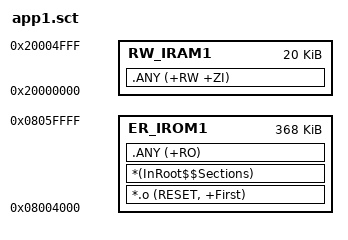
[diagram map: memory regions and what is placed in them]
; *************************************************************
; *** APP1 Scatter-Loading Description File ***
; *************************************************************

LR_IROM1 0x08004000 0x00005C00  {    ; APP1区域: 24KB
  ER_IROM1 0x08004000 0x0005C000  {  ; load address = execution address
   *.o (RESET, +First)
   *(InRoot$$Sections)
   .ANY (+RO)
  }
  RW_IRAM1 0x20000000 0x00005000  {  ; RW data: 20KB SRAM
   .ANY (+RW +ZI)
  }
}

